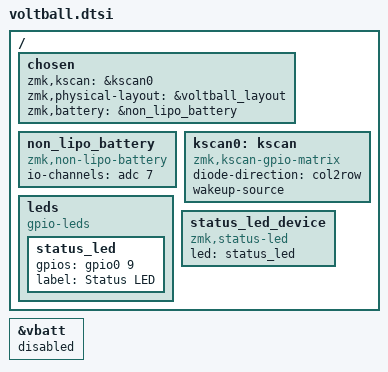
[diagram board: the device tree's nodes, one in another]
/*
 * SPDX-License-Identifier: MIT
 */

#include <dt-bindings/zmk/matrix_transform.h>
#include "voltball-layout.dtsi"
#include <input/processors.dtsi>
#include <dt-bindings/zmk/input_transform.h>
/ {
    chosen {
        zmk,kscan = &kscan0;
        zmk,physical-layout = &voltball_layout;
        zmk,battery = &non_lipo_battery;
    };

    non_lipo_battery: non_lipo_battery {
        compatible = "zmk,non-lipo-battery";
        /* P0.31/AIN7 reads half the AA voltage through the 1M/1M divider. */
        io-channels = <&adc 7>;
    };

    kscan0: kscan {
        compatible = "zmk,kscan-gpio-matrix";
        diode-direction = "col2row";
        wakeup-source;
    };

    leds {
        compatible = "gpio-leds";

        status_led: status_led {
            gpios = <&gpio0 9 GPIO_ACTIVE_HIGH>;
            label = "Status LED";
        };
    };

    status_led_device: status_led_device {
        compatible = "zmk,status-led";
        led = <&status_led>;
    };

};

&vbatt { status = "disabled"; };
